# STM32L552xx register map
File version: 1.0
Registers are 32-bit, read-write, reset 0x0 unless marked. A register's access mark holds for its fields unless they carry their own. Offsets are from the block's base; [hi:lo] are bit positions; {n}, {i} and the like mark numbered series.

## PWR — Power Control
Base 0x40007000
Same registers: PWR_S 0x50007000
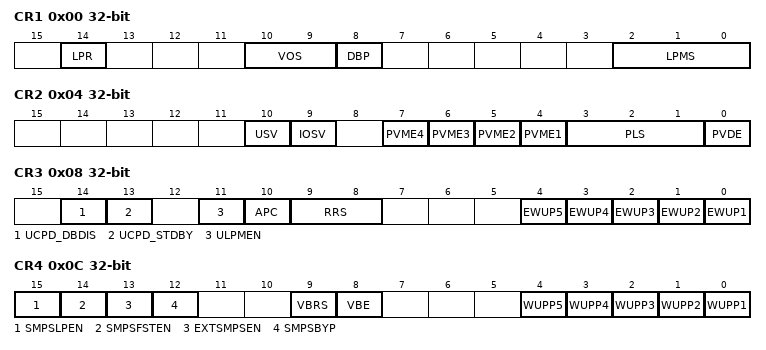
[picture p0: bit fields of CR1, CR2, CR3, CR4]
0x00 CR1 — PWR power control register 1
  [14] LPR — Regulator low-power mode
  [10:9] VOS — VOS[1:0] bits (Regulator voltage scaling output selection)
    0=SCALE0; 1=SCALE1; 2=SCALE2
  [8] DBP — Disable Back-up domain Protection
  [2:0] LPMS — Low-power mode selection field
    0=STOP0; 1=STOP1; 2=STOP2; 3=STANDBY; 4=SHUTDOWN
0x04 CR2 — PWR power control register 2
  [10] USV — VDD USB Supply Valid
  [9] IOSV — VDD IO2 independent I/Os Supply Valid
  [n+3] PVME{n} (n=1..4) — PVM {n} Enable
  [3:1] PLS — PVD level selection
    {v}=PVDLEVEL_{v} (v=0..7)
  [0] PVDE — Power Voltage Detector Enable
0x08 CR3 — PWR power control register 3
  [14] UCPD_DBDIS — Dead Battery Behavior Disable
  [13] UCPD_STDBY — UCPD Configuration memorize when enter in STANDBY
  [11] ULPMEN — Ultra Low Power Mode Enable
  [10] APC — Apply pull-up and pull-down configuration
  [9:8] RRS — RRS[1:0] bits (Ram retention in STANDBY mode)
    0=NO_RETENTION; 1=FULL_RETENTION; 2=SRAM2_4KB_RETENTION
  [n-1] EWUP{n} (n=1..5) — Enable Wake-Up Pin {n}
0x0C CR4 — PWR power control register 4
  [15] SMPSLPEN — SMPS low-power mode
  [14] SMPSFSTEN — SMPS fast soft start
  [13] EXTSMPSEN — External SMPS mode
  [12] SMPSBYP — SMPS Bypass mode
  [9] VBRS — VBAT Battery charging Resistor Selection
    0=CHARG_RESISTOR_5K; 1=CHARGRESISTOR_1_5K
  [8] VBE — VBAT Battery charging Enable
  [n-1] WUPP{n} (n=1..5) — Wake-Up Pin {n} polarity
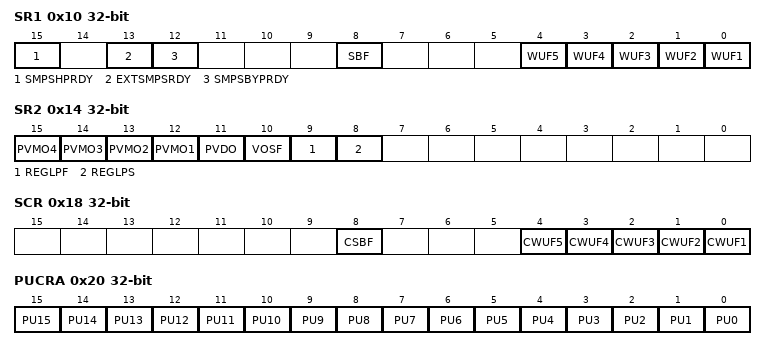
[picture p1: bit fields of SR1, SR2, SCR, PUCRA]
0x10 SR1 — PWR power status register 1
  [15] SMPSHPRDY — SMPS High-power mode ready
  [13] EXTSMPSRDY — External SMPS mode ready
  [12] SMPSBYPRDY — SMPS Bypass ready
  [8] SBF — Stand-By Flag
  [n-1] WUF{n} (n=1..5) — Wake-up Flag {n}
0x14 SR2 — PWR power status register 2
  [n+11] PVMO{n} (n=1..4) — Peripheral Voltage Monitoring Output {n}
  [11] PVDO — Power Voltage Detector Output
  [10] VOSF — Voltage Scaling Flag
  [9] REGLPF — Low-power Regulator Flag
  [8] REGLPS — Low-power Regulator Started
0x18 SCR — PWR power status clear register
  [8] CSBF — Clear Stand-By Flag
  [n-1] CWUF{n} (n=1..5) — Clear Wake-up Flag {n}
0x20 PUCRA — Pull_up control register of portA
  [n] PU{n} (n=0..15) — Port PA{n} Pull-Up set
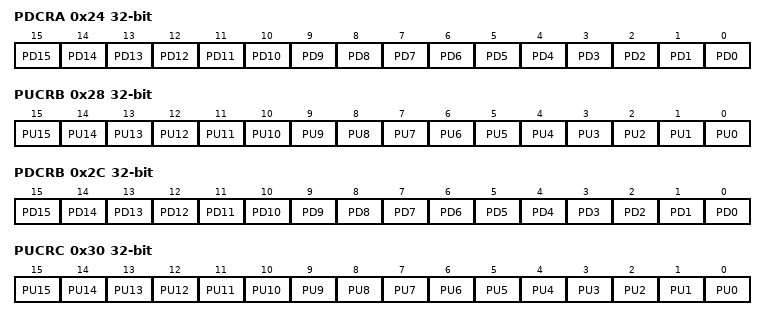
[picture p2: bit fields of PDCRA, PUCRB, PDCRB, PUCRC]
0x24 PDCRA — Pull_Down control register of portA
  [n] PD{n} (n=0..15) — Port PA{n} Pull-Down set
0x28 PUCRB — Pull_up control register of portB
  [n] PU{n} (n=0..15) — Port PB{n} Pull-Up set
0x2C PDCRB — Pull_Down control register of portB
  [n] PD{n} (n=0..15) — Port PB{n} Pull-Down set
0x30 PUCRC — Pull_up control register of portC
  [n] PU{n} (n=0..15) — Port PC{n} Pull-Up set
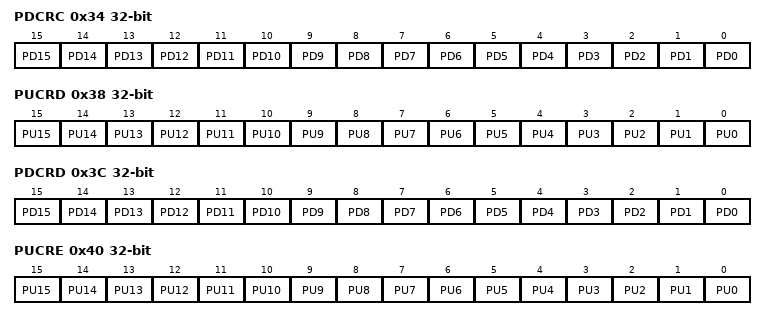
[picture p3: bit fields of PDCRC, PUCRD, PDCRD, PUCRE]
0x34 PDCRC — Pull_Down control register of portC
  [n] PD{n} (n=0..15) — Port PC{n} Pull-Down set
0x38 PUCRD — Pull_up control register of portD
  [n] PU{n} (n=0..15) — Port PD{n} Pull-Up set
0x3C PDCRD — Pull_Down control register of portD
  [n] PD{n} (n=0..15) — Port PD{n} Pull-Down set
0x40 PUCRE — Pull_up control register of portE
  [n] PU{n} (n=0..15) — Port PE{n} Pull-Up set
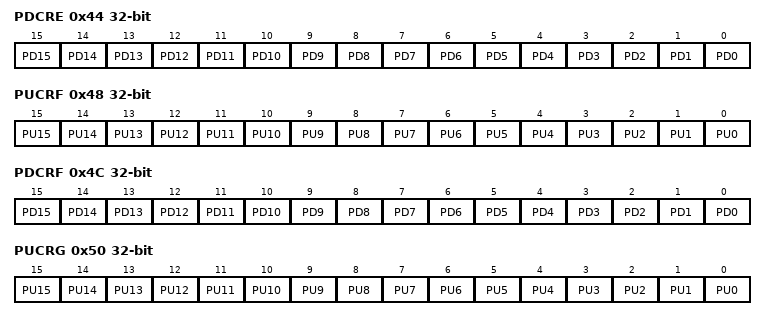
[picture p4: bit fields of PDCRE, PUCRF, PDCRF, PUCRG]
0x44 PDCRE — Pull_Down control register of portE
  [n] PD{n} (n=0..15) — Port PE{n} Pull-Down set
0x48 PUCRF — Pull_up control register of portF
  [n] PU{n} (n=0..15) — Port PF{n} Pull-Up set
0x4C PDCRF — Pull_Down control register of portF
  [n] PD{n} (n=0..15) — Port PF{n} Pull-Down set
0x50 PUCRG — Pull_up control register of portG
  [n] PU{n} (n=0..15) — Port PG{n} Pull-Up set
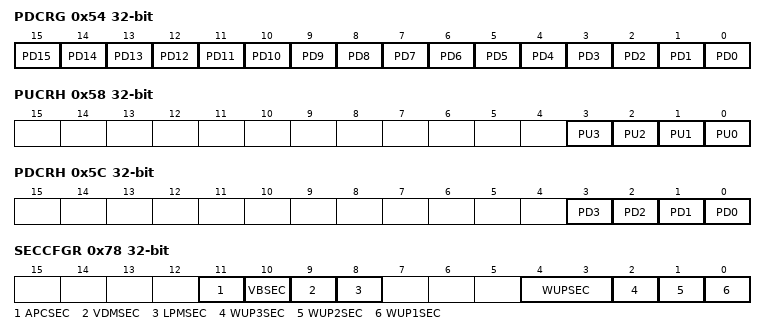
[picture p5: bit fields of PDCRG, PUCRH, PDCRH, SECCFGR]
0x54 PDCRG — Pull_Down control register of portG
  [n] PD{n} (n=0..15) — Port PG{n} Pull-Down set
0x58 PUCRH — Pull_up control register of portH
  [n] PU{n} (n=0..3) — Port PH{n} Pull-Up set
0x5C PDCRH — Pull_Down control register of portH
  [n] PD{n} (n=0..3) — Port PH{n} Pull-Down set
0x78 SECCFGR — PWR secure configuration register
  [11] APCSEC — Secure Mode Pull-Up/Down Control
  [10] VBSEC — Secure Mode VBAT
  [9] VDMSEC — Secure Mode Voltage Detection and Monitoring
  [8] LPMSEC — Secure Mode Low Power Modes
  [4:3] WUPSEC — Secure Mode Wake-Up Pins
  [2] WUP3SEC — Secure Mode Wake-Up Pin 3
  [1] WUP2SEC — Secure Mode Wake-Up Pin 2
  [0] WUP1SEC — Secure Mode Wake-Up Pin 1
0x80 PRIVCFGR — PWR privilege configuration register
  [0] PRIV — Privileged access protection
